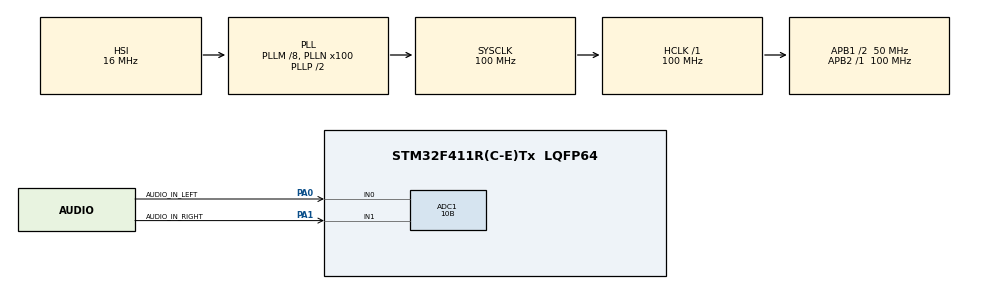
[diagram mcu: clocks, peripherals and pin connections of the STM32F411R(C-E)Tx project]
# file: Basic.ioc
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ADC1.Channel-0\#ChannelRegularConversion=ADC_CHANNEL_0
ADC1.Channel-1\#ChannelRegularConversion=ADC_CHANNEL_0
ADC1.ClockPrescaler=ADC_CLOCK_SYNC_PCLK_DIV4
ADC1.ContinuousConvMode=ENABLE
ADC1.DMAContinuousRequests=ENABLE
ADC1.DataAlign=ADC_DATAALIGN_RIGHT
ADC1.DiscontinuousConvMode=DISABLE
ADC1.EOCSelection=ADC_EOC_SEQ_CONV
ADC1.EnableAnalogWatchDog=false
ADC1.ExternalTrigConvEdge=ADC_EXTERNALTRIGCONVEDGE_NONE
ADC1.InjNumberOfConversion=0
ADC1.NbrOfConversion=2
ADC1.NbrOfConversionFlag=1
ADC1.Rank-0\#ChannelRegularConversion=1
ADC1.Rank-1\#ChannelRegularConversion=2
ADC1.Resolution=ADC_RESOLUTION_10B
ADC1.SamplingTime-0\#ChannelRegularConversion=ADC_SAMPLETIME_3CYCLES
ADC1.SamplingTime-1\#ChannelRegularConversion=ADC_SAMPLETIME_3CYCLES
ADC1.ScanConvMode=DISABLE
ADC1.master=1
Dma.ADC1.0.Direction=DMA_PERIPH_TO_MEMORY
Dma.ADC1.0.FIFOMode=DMA_FIFOMODE_DISABLE
Dma.ADC1.0.Instance=DMA2_Stream0
Dma.ADC1.0.MemDataAlignment=DMA_MDATAALIGN_HALFWORD
Dma.ADC1.0.MemInc=DMA_MINC_ENABLE
Dma.ADC1.0.Mode=DMA_CIRCULAR
Dma.ADC1.0.PeriphDataAlignment=DMA_PDATAALIGN_HALFWORD
Dma.ADC1.0.PeriphInc=DMA_PINC_DISABLE
Dma.ADC1.0.Priority=DMA_PRIORITY_LOW
Dma.Request0=ADC1
FREERTOS.Tasks01=manageLedTask,0,128,ManageLed,Default;dataAnalyzeTask,1,128,AnalyzeData,Default
Mcu.Family=STM32F4
Mcu.Name=STM32F411R(C-E)Tx
Mcu.Package=LQFP64
NVIC.DMA2_Stream0_IRQn=true\:5\:0\:false\:false\:true\:true
NVIC.PriorityGroup=NVIC_PRIORITYGROUP_4
NVIC.TIM1_UP_TIM10_IRQn=true\:0\:0\:false\:false\:true\:false
NVIC.TimeBase=TIM1_UP_TIM10_IRQn
NVIC.TimeBaseIP=TIM1
PA0-WKUP.GPIO_Label=AUDIO_IN_LEFT
PA0-WKUP.Signal=ADCx_IN0
PA1.GPIO_Label=AUDIO_IN_RIGHT
PA1.Signal=ADCx_IN1
ProjectManager.HeapSize=0x200
ProjectManager.StackSize=0x400
ProjectManager.TargetToolchain=Other Toolchains (GPDSC)
RCC.48MHZClocksFreq_Value=50000000
RCC.AHBFreq_Value=100000000
RCC.APB1CLKDivider=RCC_HCLK_DIV2
RCC.APB1Freq_Value=50000000
RCC.APB1TimFreq_Value=100000000
RCC.APB2Freq_Value=100000000
RCC.APB2TimFreq_Value=100000000
RCC.CortexFreq_Value=100000000
RCC.HCLKFreq_Value=100000000
RCC.HSE_VALUE=25000000
RCC.HSI_VALUE=16000000
RCC.LSE_VALUE=32768
RCC.PLLM=8
RCC.PLLN=100
RCC.SYSCLKFreq_VALUE=100000000
RCC.SYSCLKSource=RCC_SYSCLKSOURCE_PLLCLK
RCC.VCOOutputFreq_Value=200000000
SH.ADCx_IN0.0=ADC1_IN0,IN0
SH.ADCx_IN1.0=ADC1_IN1,IN1
VP_FREERTOS_VS_ENABLE.Mode=Enabled
VP_SYS_VS_tim1.Mode=TIM1
board=Basic

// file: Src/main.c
/**
  ******************************************************************************
  * File Name          : main.c
  * Description        : Main program body
  ******************************************************************************
  *
  * COPYRIGHT(c) 2016 STMicroelectronics
  *
  * Redistribution and use in source and binary forms, with or without modification,
  * are permitted provided that the following conditions are met:
  *   1. Redistributions of source code must retain the above copyright notice,
  *      this list of conditions and the following disclaimer.
  *   2. Redistributions in binary form must reproduce the above copyright notice,
  *      this list of conditions and the following disclaimer in the documentation
  *      and/or other materials provided with the distribution.
  *   3. Neither the name of STMicroelectronics nor the names of its contributors
  *      may be used to endorse or promote products derived from this software
  *      without specific prior written permission.
  *
  * THIS SOFTWARE IS PROVIDED BY THE COPYRIGHT HOLDERS AND CONTRIBUTORS "AS IS"
  * AND ANY EXPRESS OR IMPLIED WARRANTIES, INCLUDING, BUT NOT LIMITED TO, THE
  * IMPLIED WARRANTIES OF MERCHANTABILITY AND FITNESS FOR A PARTICULAR PURPOSE ARE
  * DISCLAIMED. IN NO EVENT SHALL THE COPYRIGHT HOLDER OR CONTRIBUTORS BE LIABLE
  * FOR ANY DIRECT, INDIRECT, INCIDENTAL, SPECIAL, EXEMPLARY, OR CONSEQUENTIAL
  * DAMAGES (INCLUDING, BUT NOT LIMITED TO, PROCUREMENT OF SUBSTITUTE GOODS OR
  * SERVICES; LOSS OF USE, DATA, OR PROFITS; OR BUSINESS INTERRUPTION) HOWEVER
  * CAUSED AND ON ANY THEORY OF LIABILITY, WHETHER IN CONTRACT, STRICT LIABILITY,
  * OR TORT (INCLUDING NEGLIGENCE OR OTHERWISE) ARISING IN ANY WAY OUT OF THE USE
  * OF THIS SOFTWARE, EVEN IF ADVISED OF THE POSSIBILITY OF SUCH DAMAGE.
  *
  ******************************************************************************
  */
#include "stm32f4xx_hal.h"
#include "cmsis_os.h"

ADC_HandleTypeDef hadc1;
DMA_HandleTypeDef hdma_adc1;

osThreadId manageLedTaskHandle;
osThreadId dataAnalyzerTasHandle;

/* USER CODE BEGIN PV */
/* Private variables ---------------------------------------------------------*/

/* USER CODE END PV */

void SystemClock_Config(void);
void Error_Handler(void);
static void MX_GPIO_Init(void);
static void MX_DMA_Init(void);
static void MX_ADC1_Init(void);
void ManageLed(void const * argument);
void DataAnalyzer(void const * argument);

/* USER CODE BEGIN PFP */
/* Private function prototypes -----------------------------------------------*/

/* USER CODE END PFP */

int main(void)
{

  /* MCU Configuration----------------------------------------------------------*/

  /* Reset of all peripherals, Initializes the Flash interface and the Systick. */
  HAL_Init();

  /* Configure the system clock */
  SystemClock_Config();

  /* Initialize all configured peripherals */
  MX_GPIO_Init();
  MX_DMA_Init();
  MX_ADC1_Init();

  /* USER CODE BEGIN 2 */
  HAL_TIM_Base_Start(&htim2);
  HAL_TIM_PWM_Start(&htim2,TIM_CHANNEL_1);
  /* USER CODE END 2 */

  /* Create the thread(s) */
  /* definition and creation of manageLedTask */
  osThreadDef(manageLedTask, ManageLed, osPriorityNormal, 0, 128);
  manageLedTaskHandle = osThreadCreate(osThread(manageLedTask), NULL);

  /* definition and creation of dataAnalyzerTas */
  osThreadDef(dataAnalyzerTas, DataAnalyzer, osPriorityAboveNormal, 0, 128);
  dataAnalyzerTasHandle = osThreadCreate(osThread(dataAnalyzerTas), NULL);

  /* Start scheduler */
  osKernelStart();

  /* We should never get here as control is now taken by the scheduler */

  /* Infinite loop */
  while (1)
  {

  }

}

/** System Clock Configuration
*/
void SystemClock_Config(void)
{

  RCC_OscInitTypeDef RCC_OscInitStruct;
  RCC_ClkInitTypeDef RCC_ClkInitStruct;

  __HAL_RCC_PWR_CLK_ENABLE();

  __HAL_PWR_VOLTAGESCALING_CONFIG(PWR_REGULATOR_VOLTAGE_SCALE1);

  RCC_OscInitStruct.OscillatorType = RCC_OSCILLATORTYPE_HSI;
  RCC_OscInitStruct.HSIState = RCC_HSI_ON;
  RCC_OscInitStruct.HSICalibrationValue = 16;
  RCC_OscInitStruct.PLL.PLLState = RCC_PLL_ON;
  RCC_OscInitStruct.PLL.PLLSource = RCC_PLLSOURCE_HSI;
  RCC_OscInitStruct.PLL.PLLM = 8;
  RCC_OscInitStruct.PLL.PLLN = 100;
  RCC_OscInitStruct.PLL.PLLP = RCC_PLLP_DIV2;
  RCC_OscInitStruct.PLL.PLLQ = 4;
  if (HAL_RCC_OscConfig(&RCC_OscInitStruct) != HAL_OK)
  {
    Error_Handler();
  }

  RCC_ClkInitStruct.ClockType = RCC_CLOCKTYPE_HCLK|RCC_CLOCKTYPE_SYSCLK
                              |RCC_CLOCKTYPE_PCLK1|RCC_CLOCKTYPE_PCLK2;
  RCC_ClkInitStruct.SYSCLKSource = RCC_SYSCLKSOURCE_PLLCLK;
  RCC_ClkInitStruct.AHBCLKDivider = RCC_SYSCLK_DIV1;
  RCC_ClkInitStruct.APB1CLKDivider = RCC_HCLK_DIV2;
  RCC_ClkInitStruct.APB2CLKDivider = RCC_HCLK_DIV1;
  if (HAL_RCC_ClockConfig(&RCC_ClkInitStruct, FLASH_LATENCY_3) != HAL_OK)
  {
    Error_Handler();
  }

  HAL_SYSTICK_Config(HAL_RCC_GetHCLKFreq()/1000);

  HAL_SYSTICK_CLKSourceConfig(SYSTICK_CLKSOURCE_HCLK);

  /* SysTick_IRQn interrupt configuration */
  HAL_NVIC_SetPriority(SysTick_IRQn, 15, 0);
}

/* ADC1 init function */
static void MX_ADC1_Init(void)
{

  ADC_ChannelConfTypeDef sConfig;

    /**Configure the global features of the ADC (Clock, Resolution, Data Alignment and number of conversion)
    */
  hadc1.Instance = ADC1;
  hadc1.Init.ClockPrescaler = ADC_CLOCK_SYNC_PCLK_DIV4;
  hadc1.Init.Resolution = ADC_RESOLUTION_10B;
  hadc1.Init.ScanConvMode = DISABLE;
  hadc1.Init.ContinuousConvMode = ENABLE;
  hadc1.Init.DiscontinuousConvMode = DISABLE;
  hadc1.Init.ExternalTrigConvEdge = ADC_EXTERNALTRIGCONVEDGE_NONE;
  hadc1.Init.DataAlign = ADC_DATAALIGN_RIGHT;
  hadc1.Init.NbrOfConversion = 2;
  hadc1.Init.DMAContinuousRequests = ENABLE;
  hadc1.Init.EOCSelection = ADC_EOC_SEQ_CONV;
  if (HAL_ADC_Init(&hadc1) != HAL_OK)
  {
    Error_Handler();
  }

    /**Configure for the selected ADC regular channel its corresponding rank in the sequencer and its sample time.
    */
  sConfig.Channel = ADC_CHANNEL_0;
  sConfig.Rank = 1;
  sConfig.SamplingTime = ADC_SAMPLETIME_3CYCLES;
  if (HAL_ADC_ConfigChannel(&hadc1, &sConfig) != HAL_OK)
  {
    Error_Handler();
  }

    /**Configure for the selected ADC regular channel its corresponding rank in the sequencer and its sample time.
    */
  sConfig.Rank = 2;
  if (HAL_ADC_ConfigChannel(&hadc1, &sConfig) != HAL_OK)
  {
    Error_Handler();
  }

}

static void MX_DMA_Init(void)
{
  /* DMA controller clock enable */
  __HAL_RCC_DMA2_CLK_ENABLE();

  /* DMA interrupt init */
  /* DMA2_Stream0_IRQn interrupt configuration */
  HAL_NVIC_SetPriority(DMA2_Stream0_IRQn, 5, 0);
  HAL_NVIC_EnableIRQ(DMA2_Stream0_IRQn);

}

/** Pinout Configuration
*/
static void MX_GPIO_Init(void)
{

  /* GPIO Ports Clock Enable */
  __HAL_RCC_GPIOA_CLK_ENABLE();

}

/* ManageLed function */
void ManageLed(void const * argument)
{

  /* USER CODE BEGIN 5 */
  /* Infinite loop */
  for(;;)
  {
    HAL_GPIO_TogglePin(GPIOA, GPIO_PIN_5);

    osDelay(100);
  }
  /* USER CODE END 5 */
}

/* DataAnalyzer function */
void DataAnalyzer(void const * argument)
{
  for(;;)
  {
    osDelay(1);
  }
}

void HAL_TIM_PeriodElapsedCallback(TIM_HandleTypeDef *htim)
{
  if (htim->Instance == TIM1) {
    HAL_IncTick();
  }
}

void Error_Handler(void)
{
  while(1)
  {
  }
}

/************************ (C) COPYRIGHT STMicroelectronics *****END OF FILE****/
